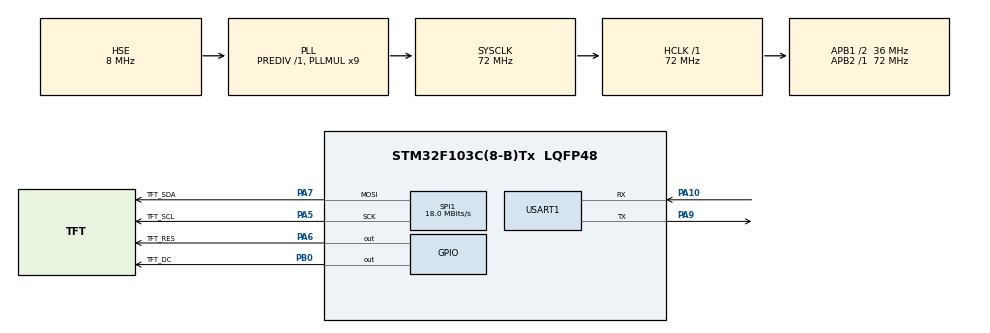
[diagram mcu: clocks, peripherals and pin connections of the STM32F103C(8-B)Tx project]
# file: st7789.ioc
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FREERTOS.INCLUDE_pcTaskGetTaskName=1
FREERTOS.INCLUDE_uxTaskGetStackHighWaterMark=1
FREERTOS.INCLUDE_vTaskDelayUntil=1
FREERTOS.INCLUDE_xTaskGetCurrentTaskHandle=1
FREERTOS.INCLUDE_xTaskGetHandle=1
FREERTOS.Tasks01=defaultTask,0,128,StartDefaultTask,Default,NULL,Dynamic,NULL,NULL;TFT_task,-3,1024,StartTFT,As weak,NULL,Static,TFT_taskBuffer,TFT_taskControlBlock
FREERTOS.configCHECK_FOR_STACK_OVERFLOW=2
FREERTOS.configMINIMAL_STACK_SIZE=64
FREERTOS.configTOTAL_HEAP_SIZE=1024
FREERTOS.configUSE_COUNTING_SEMAPHORES=1
FREERTOS.configUSE_NEWLIB_REENTRANT=0
FREERTOS.configUSE_TIMERS=0
Mcu.Family=STM32F1
Mcu.Name=STM32F103C(8-B)Tx
Mcu.Package=LQFP48
Mcu.UserConstants=UART_PRINTF,USART1
NVIC.PriorityGroup=NVIC_PRIORITYGROUP_4
NVIC.TIM1_UP_IRQn=true\:15\:0\:false\:false\:true\:false\:false\:true\:true
NVIC.TimeBase=TIM1_UP_IRQn
NVIC.TimeBaseIP=TIM1
PA10.Mode=Asynchronous
PA10.Signal=USART1_RX
PA13.Mode=Serial_Wire
PA13.Signal=SYS_JTMS-SWDIO
PA14.Mode=Serial_Wire
PA14.Signal=SYS_JTCK-SWCLK
PA5.GPIO_Label=TFT_SCL
PA5.Mode=TX_Only_Simplex_Unidirect_Master
PA5.Signal=SPI1_SCK
PA6.GPIO_Label=TFT_RES
PA6.GPIO_Speed=GPIO_SPEED_FREQ_HIGH
PA6.Signal=GPIO_Output
PA7.GPIO_Label=TFT_SDA
PA7.Mode=TX_Only_Simplex_Unidirect_Master
PA7.Signal=SPI1_MOSI
PA9.Mode=Asynchronous
PA9.Signal=USART1_TX
PB0.GPIO_Label=TFT_DC
PB0.GPIO_Speed=GPIO_SPEED_FREQ_HIGH
PB0.Signal=GPIO_Output
PD0-OSC_IN.Mode=HSE-External-Oscillator
PD0-OSC_IN.Signal=RCC_OSC_IN
PD1-OSC_OUT.Mode=HSE-External-Oscillator
PD1-OSC_OUT.Signal=RCC_OSC_OUT
ProjectManager.HeapSize=0x10
ProjectManager.StackSize=0x400
ProjectManager.TargetToolchain=MDK-ARM V5.32
RCC.AHBFreq_Value=72000000
RCC.APB1CLKDivider=RCC_HCLK_DIV2
RCC.APB1Freq_Value=36000000
RCC.APB1TimFreq_Value=72000000
RCC.APB2Freq_Value=72000000
RCC.APB2TimFreq_Value=72000000
RCC.HCLKFreq_Value=72000000
RCC.PLLMUL=RCC_PLL_MUL9
RCC.PLLSourceVirtual=RCC_PLLSOURCE_HSE
RCC.SYSCLKFreq_VALUE=72000000
RCC.SYSCLKSource=RCC_SYSCLKSOURCE_PLLCLK
RCC.USBFreq_Value=72000000
SPI1.BaudRatePrescaler=SPI_BAUDRATEPRESCALER_4
SPI1.CalculateBaudRate=18.0 MBits/s
SPI1.Direction=SPI_DIRECTION_2LINES
SPI1.Mode=SPI_MODE_MASTER
SPI1.VirtualType=VM_MASTER
USART1.VirtualMode=VM_ASYNC
VP_FREERTOS_VS_CMSIS_V1.Mode=CMSIS_V1
VP_SYS_VS_tim1.Mode=TIM1
board=custom

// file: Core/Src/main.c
/* USER CODE BEGIN Header */
/**
  ******************************************************************************
  * @file           : main.c
  * @brief          : Main program body
  ******************************************************************************
  * @attention
  *
  * Copyright (c) 2023 STMicroelectronics.
  * All rights reserved.
  *
  * This software is licensed under terms that can be found in the LICENSE file
  * in the root directory of this software component.
  * If no LICENSE file comes with this software, it is provided AS-IS.
  *
  ******************************************************************************
  */
/* USER CODE END Header */
#include "main.h"
#include "cmsis_os.h"
#include "spi.h"
#include "usart.h"
#include "gpio.h"

/* USER CODE BEGIN Includes */
#include "ST7789/core.h"
#include "ST7789/lv_driver.h"
/* USER CODE END Includes */

void SystemClock_Config(void);
void MX_FREERTOS_Init(void);

int main(void)
{

  /* MCU Configuration--------------------------------------------------------*/

  /* Reset of all peripherals, Initializes the Flash interface and the Systick. */
  HAL_Init();

  /* Configure the system clock */
  SystemClock_Config();

  /* Initialize all configured peripherals */
  MX_GPIO_Init();
  MX_SPI1_Init();
  MX_USART1_UART_Init();

  /* Call init function for freertos objects (in freertos.c) */
  //MX_FREERTOS_Init();

  /* Start scheduler */
  //osKernelStart();

  /* We should never get here as control is now taken by the scheduler */
  /* Infinite loop */
  /* USER CODE BEGIN WHILE */
  LCD_Init();
  HAL_Delay(100);
  POINT_COLOR = BLUE;
  LCD_ShowString(0,0,240,240,24,"HELLO WORLD");
  LCD_ShowString(0,32,240,240,24,"Lovelessing...");

  while (1)
  {
    /* USER CODE END WHILE */

  }
}

void SystemClock_Config(void)
{
  RCC_OscInitTypeDef RCC_OscInitStruct = {0};
  RCC_ClkInitTypeDef RCC_ClkInitStruct = {0};

  /** Initializes the RCC Oscillators according to the specified parameters
  * in the RCC_OscInitTypeDef structure.
  */
  RCC_OscInitStruct.OscillatorType = RCC_OSCILLATORTYPE_HSE;
  RCC_OscInitStruct.HSEState = RCC_HSE_ON;
  RCC_OscInitStruct.HSEPredivValue = RCC_HSE_PREDIV_DIV1;
  RCC_OscInitStruct.HSIState = RCC_HSI_ON;
  RCC_OscInitStruct.PLL.PLLState = RCC_PLL_ON;
  RCC_OscInitStruct.PLL.PLLSource = RCC_PLLSOURCE_HSE;
  RCC_OscInitStruct.PLL.PLLMUL = RCC_PLL_MUL9;
  if (HAL_RCC_OscConfig(&RCC_OscInitStruct) != HAL_OK)
  {
    Error_Handler();
  }

  /** Initializes the CPU, AHB and APB buses clocks
  */
  RCC_ClkInitStruct.ClockType = RCC_CLOCKTYPE_HCLK|RCC_CLOCKTYPE_SYSCLK
                              |RCC_CLOCKTYPE_PCLK1|RCC_CLOCKTYPE_PCLK2;
  RCC_ClkInitStruct.SYSCLKSource = RCC_SYSCLKSOURCE_PLLCLK;
  RCC_ClkInitStruct.AHBCLKDivider = RCC_SYSCLK_DIV1;
  RCC_ClkInitStruct.APB1CLKDivider = RCC_HCLK_DIV2;
  RCC_ClkInitStruct.APB2CLKDivider = RCC_HCLK_DIV1;

  if (HAL_RCC_ClockConfig(&RCC_ClkInitStruct, FLASH_LATENCY_2) != HAL_OK)
  {
    Error_Handler();
  }
}

void HAL_TIM_PeriodElapsedCallback(TIM_HandleTypeDef *htim)
{
  if (htim->Instance == TIM1) {
    HAL_IncTick();
  }
}

void Error_Handler(void)
{
  __disable_irq();
  while (1)
  {
  }
}
